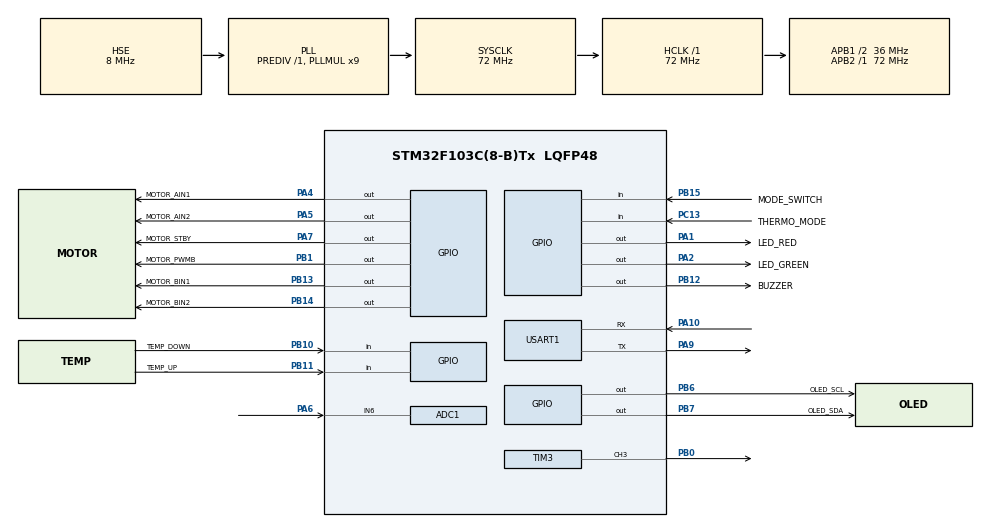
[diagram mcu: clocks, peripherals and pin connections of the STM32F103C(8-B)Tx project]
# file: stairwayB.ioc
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ADC1.Channel-0\#ChannelRegularConversion=ADC_CHANNEL_6
ADC1.ContinuousConvMode=ENABLE
ADC1.NbrOfConversionFlag=1
ADC1.Rank-0\#ChannelRegularConversion=1
ADC1.SamplingTime-0\#ChannelRegularConversion=ADC_SAMPLETIME_1CYCLE_5
ADC1.master=1
Dma.ADC1.0.Direction=DMA_PERIPH_TO_MEMORY
Dma.ADC1.0.Instance=DMA1_Channel1
Dma.ADC1.0.MemDataAlignment=DMA_MDATAALIGN_HALFWORD
Dma.ADC1.0.MemInc=DMA_MINC_ENABLE
Dma.ADC1.0.Mode=DMA_CIRCULAR
Dma.ADC1.0.PeriphDataAlignment=DMA_PDATAALIGN_HALFWORD
Dma.ADC1.0.PeriphInc=DMA_PINC_DISABLE
Dma.ADC1.0.Priority=DMA_PRIORITY_LOW
Dma.Request0=ADC1
Mcu.Family=STM32F1
Mcu.Name=STM32F103C(8-B)Tx
Mcu.Package=LQFP48
NVIC.DMA1_Channel1_IRQn=true\:0\:0\:false\:false\:true\:false\:true\:true
NVIC.PriorityGroup=NVIC_PRIORITYGROUP_4
PA1.GPIO_Label=LED_RED
PA1.Signal=GPIO_Output
PA10.Mode=Asynchronous
PA10.Signal=USART1_RX
PA13.Mode=Serial_Wire
PA13.Signal=SYS_JTMS-SWDIO
PA14.Mode=Serial_Wire
PA14.Signal=SYS_JTCK-SWCLK
PA2.GPIO_Label=LED_GREEN
PA2.Signal=GPIO_Output
PA4.GPIO_Label=MOTOR_AIN1
PA4.Signal=GPIO_Output
PA5.GPIO_Label=MOTOR_AIN2
PA5.Signal=GPIO_Output
PA6.Signal=ADCx_IN6
PA7.GPIO_Label=MOTOR_STBY
PA7.Signal=GPIO_Output
PA9.Mode=Asynchronous
PA9.Signal=USART1_TX
PB0.Signal=S_TIM3_CH3
PB1.GPIO_Label=MOTOR_PWMB
PB1.Signal=GPIO_Output
PB10.GPIO_Label=TEMP_DOWN
PB10.GPIO_PuPd=GPIO_NOPULL
PB10.Signal=GPIO_Input
PB11.GPIO_Label=TEMP_UP
PB11.GPIO_PuPd=GPIO_NOPULL
PB11.Signal=GPIO_Input
PB12.GPIO_Label=BUZZER
PB12.Signal=GPIO_Output
PB13.GPIO_Label=MOTOR_BIN1
PB13.Signal=GPIO_Output
PB14.GPIO_Label=MOTOR_BIN2
PB14.Signal=GPIO_Output
PB15.GPIO_Label=MODE_SWITCH
PB15.GPIO_PuPd=GPIO_NOPULL
PB15.Signal=GPIO_Input
PB6.GPIO_Label=OLED_SCL
PB6.GPIO_ModeDefaultOutputPP=GPIO_MODE_OUTPUT_OD
PB6.GPIO_PuPd=GPIO_PULLUP
PB6.Signal=GPIO_Output
PB7.GPIO_Label=OLED_SDA
PB7.GPIO_ModeDefaultOutputPP=GPIO_MODE_OUTPUT_OD
PB7.GPIO_PuPd=GPIO_PULLUP
PB7.Signal=GPIO_Output
PC13-TAMPER-RTC.GPIO_Label=THERMO_MODE
PC13-TAMPER-RTC.GPIO_PuPd=GPIO_PULLUP
PC13-TAMPER-RTC.Signal=GPIO_Input
PD0-OSC_IN.Mode=HSE-External-Oscillator
PD0-OSC_IN.Signal=RCC_OSC_IN
PD1-OSC_OUT.Mode=HSE-External-Oscillator
PD1-OSC_OUT.Signal=RCC_OSC_OUT
ProjectManager.HeapSize=0x200
ProjectManager.StackSize=0x400
ProjectManager.TargetToolchain=MDK-ARM V5.32
RCC.ADCPresc=RCC_ADCPCLK2_DIV6
RCC.AHBFreq_Value=72000000
RCC.APB1CLKDivider=RCC_HCLK_DIV2
RCC.APB1Freq_Value=36000000
RCC.APB1TimFreq_Value=72000000
RCC.APB2Freq_Value=72000000
RCC.APB2TimFreq_Value=72000000
RCC.HCLKFreq_Value=72000000
RCC.PLLMUL=RCC_PLL_MUL9
RCC.PLLSourceVirtual=RCC_PLLSOURCE_HSE
RCC.SYSCLKFreq_VALUE=72000000
RCC.SYSCLKSource=RCC_SYSCLKSOURCE_PLLCLK
RCC.USBFreq_Value=72000000
SH.ADCx_IN6.0=ADC1_IN6,IN6
SH.S_TIM3_CH3.0=TIM3_CH3,PWM Generation3 CH3
TIM3.Channel-PWM\ Generation3\ CH3=TIM_CHANNEL_3
TIM3.Period=999
TIM3.Prescaler=71
USART1.VirtualMode=VM_ASYNC
board=custom

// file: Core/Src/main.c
/* USER CODE BEGIN Header */
/**
  ******************************************************************************
  * @file             : main.c
  * @brief            : Main program body
  ******************************************************************************
  * @attention
  *
  * Copyright (c) 2025 STMicroelectronics.
  * All rights reserved.
  *
  * This software is licensed under terms that can be found in the LICENSE file
  * in the root directory of this software component.
  * If no LICENSE file comes with this software, it is provided AS-IS.
  *
  ******************************************************************************
  */
/* USER CODE END Header */
#include "main.h"
#include "adc.h"
#include "dma.h"
#include "tim.h"
#include "usart.h"
#include "gpio.h"

/* USER CODE BEGIN Includes */
/* 应用层入口（C 接口，实现见 App/ 下的 C++ 文件）。 */
#include "app_api.h"
/* USER CODE END Includes */

void SystemClock_Config(void);

int main(void)
{

  /* MCU Configuration--------------------------------------------------------*/

  /* Reset of all peripherals, Initializes the Flash interface and the Systick. */
  HAL_Init();

  /* Configure the system clock */
  SystemClock_Config();

  /* Initialize all configured peripherals */
  MX_GPIO_Init();
  MX_DMA_Init();
  MX_ADC1_Init();
  MX_TIM3_Init();
  MX_USART1_UART_Init();
  /* USER CODE BEGIN 2 */
  /* 外设已由上面的 MX_*_Init() 初始化，这里启动应用层：
   *   app_init()  —— 读设置、启动采样与风扇驱动；
   *   app_start() —— 创建 FreeRTOS 任务并启动调度器，正常不再返回。 */
  app_init();
  app_start();  /* 不会返回 */
  /* USER CODE END 2 */

  /* Infinite loop */
  while (1)
  {

    /* USER CODE BEGIN 3 */
    /* 调度器运行期间不会走到这里；仅作兜底保留。 */
  }
  /* USER CODE END 3 */
}

void SystemClock_Config(void)
{
  RCC_OscInitTypeDef RCC_OscInitStruct = {0};
  RCC_ClkInitTypeDef RCC_ClkInitStruct = {0};
  RCC_PeriphCLKInitTypeDef PeriphClkInit = {0};

  /** Initializes the RCC Oscillators according to the specified parameters
  * in the RCC_OscInitTypeDef structure.
  */
  RCC_OscInitStruct.OscillatorType = RCC_OSCILLATORTYPE_HSE;
  RCC_OscInitStruct.HSEState = RCC_HSE_ON;
  RCC_OscInitStruct.HSEPredivValue = RCC_HSE_PREDIV_DIV1;
  RCC_OscInitStruct.HSIState = RCC_HSI_ON;
  RCC_OscInitStruct.PLL.PLLState = RCC_PLL_ON;
  RCC_OscInitStruct.PLL.PLLSource = RCC_PLLSOURCE_HSE;
  RCC_OscInitStruct.PLL.PLLMUL = RCC_PLL_MUL9;
  if (HAL_RCC_OscConfig(&RCC_OscInitStruct) != HAL_OK)
  {
    Error_Handler();
  }

  /** Initializes the CPU, AHB and APB buses clocks
  */
  RCC_ClkInitStruct.ClockType = RCC_CLOCKTYPE_HCLK|RCC_CLOCKTYPE_SYSCLK
                              |RCC_CLOCKTYPE_PCLK1|RCC_CLOCKTYPE_PCLK2;
  RCC_ClkInitStruct.SYSCLKSource = RCC_SYSCLKSOURCE_PLLCLK;
  RCC_ClkInitStruct.AHBCLKDivider = RCC_SYSCLK_DIV1;
  RCC_ClkInitStruct.APB1CLKDivider = RCC_HCLK_DIV2;
  RCC_ClkInitStruct.APB2CLKDivider = RCC_HCLK_DIV1;

  if (HAL_RCC_ClockConfig(&RCC_ClkInitStruct, FLASH_LATENCY_2) != HAL_OK)
  {
    Error_Handler();
  }
  PeriphClkInit.PeriphClockSelection = RCC_PERIPHCLK_ADC;
  PeriphClkInit.AdcClockSelection = RCC_ADCPCLK2_DIV6;
  if (HAL_RCCEx_PeriphCLKConfig(&PeriphClkInit) != HAL_OK)
  {
    Error_Handler();
  }
}

void Error_Handler(void)
{
  __disable_irq();
  while (1)
  {
  }
}
